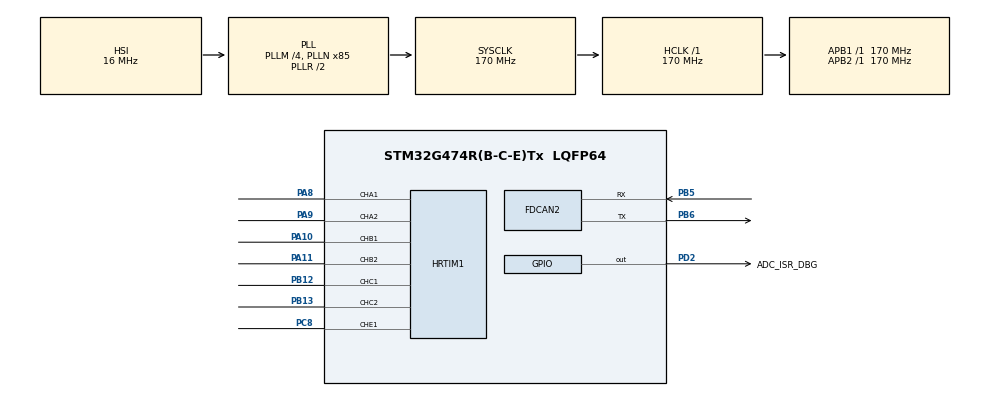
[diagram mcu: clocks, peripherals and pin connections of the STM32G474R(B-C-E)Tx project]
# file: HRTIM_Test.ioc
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FDCAN2.CalculateBaudRateNominal=499999
FDCAN2.CalculateTimeBitNominal=2000
FDCAN2.CalculateTimeQuantumNominal=58.82352941176471
FDCAN2.NominalPrescaler=10
FDCAN2.NominalTimeSeg1=25
FDCAN2.NominalTimeSeg2=8
HRTIM1.ADCTrigger1_Source1=HRTIM_ADCTRIGGEREVENT13_MASTER_PERIOD
HRTIM1.ADCTrigger_Id1=HRTIM_ADCTRIGGER_1
HRTIM1.CaptureUnit1-No_output_TD=__NULL
HRTIM1.CaptureUnit2-No_output_TD=__NULL
HRTIM1.CompareUnit1-MasterTimer=HRTIM_COMPAREUNIT_1
HRTIM1.CompareUnit1-No_output_TD=HRTIM_COMPAREUNIT_1
HRTIM1.CompareUnit1-Output_TA1TA2=__NULL
HRTIM1.CompareUnit1-Output_TB1TB2=__NULL
HRTIM1.CompareUnit1-Output_TC1TC2=__NULL
HRTIM1.CompareUnit1-Output_TE1=HRTIM_COMPAREUNIT_1
HRTIM1.CompareUnit2-MasterTimer=__NULL
HRTIM1.CompareUnit2-No_output_TD=__NULL
HRTIM1.CompareUnit2-Output_TA1TA2=HRTIM_COMPAREUNIT_2
HRTIM1.CompareUnit2-Output_TC1TC2=HRTIM_COMPAREUNIT_2
HRTIM1.CompareUnit3-MasterTimer=HRTIM_COMPAREUNIT_3
HRTIM1.CompareUnit3-No_output_TD=HRTIM_COMPAREUNIT_3
HRTIM1.CompareUnit3-Output_TA1TA2=__NULL
HRTIM1.CompareUnit3-Output_TC1TC2=__NULL
HRTIM1.CompareUnit4-MasterTimer=__NULL
HRTIM1.CompareUnit4-No_output_TD=__NULL
HRTIM1.CompareValue1-MasterTimer=1100
HRTIM1.CompareValue1-No_output_TD=110
HRTIM1.CompareValue1-Output_TE1=8160
HRTIM1.CompareValue2-Output_TA1TA2=110
HRTIM1.CompareValue2-Output_TC1TC2=359
HRTIM1.CompareValue3-MasterTimer=3000
HRTIM1.CompareValue3-No_output_TD=1100
HRTIM1.DACSynchro-MasterTimer=HRTIM_DACSYNC_NONE
HRTIM1.DACSynchro-Output_TA1TA2=HRTIM_DACSYNC_NONE
HRTIM1.DACSynchro-Output_TC1TC2=HRTIM_DACSYNC_NONE
HRTIM1.DeadTimeInsertion-Output_TA1TA2=HRTIM_TIMDEADTIMEINSERTION_DISABLED
HRTIM1.DeadTimeInsertion-Output_TB1TB2=HRTIM_TIMDEADTIMEINSERTION_DISABLED
HRTIM1.DualChannelDacEnableFake_TA-Output_TA1TA2=HRTIM_TIMER_DCDE_DISABLED
HRTIM1.DualChannelDacEnableFake_TC-Output_TC1TC2=HRTIM_TIMER_DCDE_ENABLED_FAKE1
HRTIM1.Event5-No_output_TD=HRTIM_EVENT_5
HRTIM1.Event5-Output_TA1TA2=HRTIM_EVENT_5
HRTIM1.Event_EEV1=__NULL
HRTIM1.Event_EEV2=__NULL
HRTIM1.Event_EEV3=__NULL
HRTIM1.Event_EEV4=__NULL
HRTIM1.Event_EEV5=HRTIM_EVENT_5
HRTIM1.FastMode_EEV5=HRTIM_EVENTFASTMODE_ENABLE
HRTIM1.FaultLevel1-Output_TA1TA2=HRTIM_OUTPUTFAULTLEVEL_INACTIVE
HRTIM1.Filter5-No_output_TD=HRTIM_TIMEEVFLT_BLANKINGCMP3
HRTIM1.Filter5-Output_TA1TA2=HRTIM_TIMEEVFLT_BLANKINGCMP2
HRTIM1.InterleavedMode-Output_TA1TA2=HRTIM_INTERLEAVED_MODE_DISABLED
HRTIM1.InterleavedMode-Output_TB1TB2=HRTIM_INTERLEAVED_MODE_DISABLED
HRTIM1.InterruptRequests1-Output_TA1TA2=HRTIM_TIM_IT_SET1
HRTIM1.InterruptRequests1_Master=HRTIM_MASTER_IT_NONE
HRTIM1.ModeTimeBase-No_output_TD=HRTIM_MODE_SINGLESHOT_RETRIGGERABLE
HRTIM1.ModeTimeBase-Output_TA1TA2=HRTIM_MODE_SINGLESHOT
HRTIM1.ModeTimeBase-Output_TB1TB2=HRTIM_MODE_SINGLESHOT
HRTIM1.ModeTimeBase-Output_TC1TC2=HRTIM_MODE_SINGLESHOT_RETRIGGERABLE
HRTIM1.ModeTimeBase-Output_TE1=HRTIM_MODE_SINGLESHOT
HRTIM1.NumberADCTriggerSource1=1
HRTIM1.NumberDMARequests_TA=0
HRTIM1.NumberInterruptRequests-Output_TA1TA2=1
HRTIM1.NumberInterruptRequests_Master-MasterTimer=1
HRTIM1.NumberResetSource1-Output_TA1TA2=2
HRTIM1.NumberResetSource1-Output_TB1TB2=1
HRTIM1.NumberResetSource1-Output_TC1TC2=1
HRTIM1.NumberResetSource1-Output_TE1=1
HRTIM1.NumberResetSource2_TA=2
HRTIM1.NumberResetSource2_TB=1
HRTIM1.NumberResetSource2_TC=1
HRTIM1.NumberResetTrigger-No_output_TD=2
HRTIM1.NumberResetTrigger-Output_TA1TA2=1
HRTIM1.NumberResetTrigger-Output_TB1TB2=1
HRTIM1.NumberResetTrigger-Output_TC1TC2=1
HRTIM1.NumberResetTrigger-Output_TE1=1
HRTIM1.NumberSetSource1-Output_TA1TA2=1
HRTIM1.NumberSetSource1-Output_TB1TB2=1
HRTIM1.NumberSetSource1-Output_TC1TC2=1
HRTIM1.NumberSetSource1-Output_TE1=1
HRTIM1.NumberSetSource2_TA=1
HRTIM1.NumberSetSource2_TB=1
HRTIM1.NumberSetSource2_TC=1
HRTIM1.NumberUpdateTrigger-No_output_TD=0
HRTIM1.ORingUpdateSource_ADCTrigger1=HRTIM_ADCTRIGGERUPDATE_MASTER
HRTIM1.Periode_MASTER=5440
HRTIM1.Periode_TA=5440
HRTIM1.Periode_TB=5440
HRTIM1.Periode_TC=5440
HRTIM1.Periode_TD=5440
HRTIM1.Periode_TE=21760
HRTIM1.Polarity1-Output_TA1TA2=HRTIM_OUTPUTPOLARITY_HIGH
HRTIM1.Polarity1-Output_TB1TB2=HRTIM_OUTPUTPOLARITY_LOW
HRTIM1.Polarity2-Output_TA1TA2=HRTIM_OUTPUTPOLARITY_HIGH
HRTIM1.Polarity2-Output_TB1TB2=HRTIM_OUTPUTPOLARITY_LOW
HRTIM1.Polarity_EEV5=HRTIM_EVENTPOLARITY_HIGH
HRTIM1.PreloadEnable-No_output_TD=HRTIM_PRELOAD_DISABLED
HRTIM1.PushPull-Output_TA1TA2=HRTIM_TIMPUSHPULLMODE_ENABLED
HRTIM1.PushPull-Output_TB1TB2=HRTIM_TIMPUSHPULLMODE_ENABLED
HRTIM1.PushPull-Output_TC1TC2=HRTIM_TIMPUSHPULLMODE_ENABLED
HRTIM1.ReSyncUpdate-No_output_TD=HRTIM_TIMERESYNC_UPDATE_UNCONDITIONAL
HRTIM1.ResetOutput1_Source1-Output_TA1TA2=HRTIM_OUTPUTRESET_MASTERCMP3
HRTIM1.ResetOutput1_Source1-Output_TB1TB2=HRTIM_OUTPUTRESET_TIMBEV5_TIMDCMP3
HRTIM1.ResetOutput1_Source1-Output_TC1TC2=HRTIM_OUTPUTRESET_MASTERCMP3
HRTIM1.ResetOutput1_Source1-Output_TE1=HRTIM_OUTPUTRESET_TIMCMP1
HRTIM1.ResetOutput1_Source2-Output_TA1TA2=HRTIM_OUTPUTSET_EEV_5
HRTIM1.ResetOutput2_Source1-Output_TA1TA2=HRTIM_OUTPUTRESET_MASTERCMP3
HRTIM1.ResetOutput2_Source1-Output_TB1TB2=HRTIM_OUTPUTRESET_TIMBEV5_TIMDCMP3
HRTIM1.ResetOutput2_Source1-Output_TC1TC2=HRTIM_OUTPUTRESET_MASTERCMP3
HRTIM1.ResetOutput2_Source2-Output_TA1TA2=HRTIM_OUTPUTSET_EEV_5
HRTIM1.ResetTrigger1-No_output_TD=HRTIM_TIMRESETTRIGGER_MASTER_CMP3
HRTIM1.ResetTrigger1-Output_TA1TA2=HRTIM_TIMRESETTRIGGER_MASTER_PER
HRTIM1.ResetTrigger1-Output_TB1TB2=HRTIM_TIMRESETTRIGGER_MASTER_PER
HRTIM1.ResetTrigger1-Output_TC1TC2=HRTIM_TIMRESETTRIGGER_MASTER_PER
HRTIM1.ResetTrigger1-Output_TE1=HRTIM_TIMRESETTRIGGER_MASTER_PER
HRTIM1.ResetTrigger2-No_output_TD=HRTIM_TIMRESETTRIGGER_EEV_5
HRTIM1.ResetUpdate-No_output_TD=HRTIM_TIMUPDATEONRESET_DISABLED
HRTIM1.Sensitivity_EEV5=HRTIM_EVENTSENSITIVITY_LEVEL
HRTIM1.SetOutput1_Source1-Output_TA1TA2=HRTIM_OUTPUTSET_MASTERCMP1
HRTIM1.SetOutput1_Source1-Output_TB1TB2=HRTIM_OUTPUTSET_MASTERPER
HRTIM1.SetOutput1_Source1-Output_TC1TC2=HRTIM_OUTPUTSET_MASTERPER
HRTIM1.SetOutput1_Source1-Output_TE1=HRTIM_OUTPUTSET_TIMPER
HRTIM1.SetOutput2_Source1-Output_TA1TA2=HRTIM_OUTPUTSET_MASTERCMP1
HRTIM1.SetOutput2_Source1-Output_TB1TB2=HRTIM_OUTPUTSET_MASTERPER
HRTIM1.SetOutput2_Source1-Output_TC1TC2=HRTIM_OUTPUTSET_MASTERPER
HRTIM1.UpDownMode-No_output_TD=HRTIM_TIMERUPDOWNMODE_UP
HRTIM1.postscaler1=1
Mcu.Family=STM32G4
Mcu.Name=STM32G474R(B-C-E)Tx
Mcu.Package=LQFP64
NVIC.PriorityGroup=NVIC_PRIORITYGROUP_4
PA10.Mode=Output_TB1TB2
PA10.Signal=HRTIM1_CHB1
PA11.Mode=Output_TB1TB2
PA11.Signal=HRTIM1_CHB2
PA13.GPIO_Label=T_SWDIO
PA13.Signal=SYS_JTMS-SWDIO
PA14.GPIO_Label=T_SWCLK
PA14.Signal=SYS_JTCK-SWCLK
PA8.Mode=Output_TA1TA2
PA8.Signal=HRTIM1_CHA1
PA9.Mode=Output_TA1TA2
PA9.Signal=HRTIM1_CHA2
PB12.Mode=Output_TC1TC2
PB12.Signal=HRTIM1_CHC1
PB13.Mode=Output_TC1TC2
PB13.Signal=HRTIM1_CHC2
PB3.GPIO_Label=T_SWO
PB3.Signal=SYS_JTDO-SWO
PB5.Mode=FDCAN_Activate
PB5.Signal=FDCAN2_RX
PB6.Mode=FDCAN_Activate
PB6.Signal=FDCAN2_TX
PC8.Mode=Output_TE1
PC8.Signal=HRTIM1_CHE1
PD2.GPIO_Label=ADC_ISR_DBG
PD2.GPIO_Speed=GPIO_SPEED_FREQ_VERY_HIGH
PD2.PinState=GPIO_PIN_RESET
PD2.Signal=GPIO_Output
ProjectManager.HeapSize=0x200
ProjectManager.StackSize=0x400
ProjectManager.TargetToolchain=STM32CubeIDE
RCC.ADC12Freq_Value=170000000
RCC.ADC345Freq_Value=170000000
RCC.AHBFreq_Value=170000000
RCC.APB1Freq_Value=170000000
RCC.APB1TimFreq_Value=170000000
RCC.APB2Freq_Value=170000000
RCC.APB2TimFreq_Value=170000000
RCC.CortexFreq_Value=170000000
RCC.EXTERNAL_CLOCK_VALUE=12288000
RCC.HCLKFreq_Value=170000000
RCC.HSE_VALUE=24000000
RCC.HSI48_VALUE=48000000
RCC.HSI_VALUE=16000000
RCC.LSE_VALUE=32768
RCC.PLLM=RCC_PLLM_DIV4
RCC.PLLN=85
RCC.RTCClockSelection=RCC_RTCCLKSOURCE_LSE
RCC.SYSCLKFreq_VALUE=170000000
RCC.SYSCLKSource=RCC_SYSCLKSOURCE_PLLCLK
RCC.USBFreq_Value=170000000
RCC.VCOOutputFreq_Value=340000000
VP_HRTIM1_VS_hrtimMasterTimerNoOutput.Mode=MasterTimer
VP_HRTIM1_VS_hrtimTimerDNoOutput.Mode=No_output_TD
VP_SYS_VS_DBSignals.Mode=DisableDeadBatterySignals
board=NUCLEO-G474RE

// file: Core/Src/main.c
/* USER CODE BEGIN Header */
/**
 ******************************************************************************
 * @file           : main.c
 * @brief          : Main program body
 ******************************************************************************
 * @attention
 *
 * Copyright (c) 2025 STMicroelectronics.
 * All rights reserved.
 *
 * This software is licensed under terms that can be found in the LICENSE file
 * in the root directory of this software component.
 * If no LICENSE file comes with this software, it is provided AS-IS.
 *
 ******************************************************************************
 */
/* USER CODE END Header */
#include "main.h"

FDCAN_HandleTypeDef hfdcan2;

HRTIM_HandleTypeDef hhrtim1;

void SystemClock_Config(void);
static void MX_GPIO_Init(void);
static void MX_HRTIM1_Init(void);
static void MX_FDCAN2_Init(void);

int main(void)
{

  /* MCU Configuration--------------------------------------------------------*/

  /* Reset of all peripherals, Initializes the Flash interface and the Systick. */
  HAL_Init();

  /* Configure the system clock */
  SystemClock_Config();

  /* Initialize all configured peripherals */
  MX_GPIO_Init();
  MX_HRTIM1_Init();
  MX_FDCAN2_Init();
  /* USER CODE BEGIN 2 */

    app_init();

  /* USER CODE END 2 */

  /* Infinite loop */
  /* USER CODE BEGIN WHILE */
    while (1) {
        app_loop();
    /* USER CODE END WHILE */

    }
}

void SystemClock_Config(void)
{
  RCC_OscInitTypeDef RCC_OscInitStruct = {0};
  RCC_ClkInitTypeDef RCC_ClkInitStruct = {0};

  /** Configure the main internal regulator output voltage
  */
  HAL_PWREx_ControlVoltageScaling(PWR_REGULATOR_VOLTAGE_SCALE1_BOOST);

  /** Initializes the RCC Oscillators according to the specified parameters
  * in the RCC_OscInitTypeDef structure.
  */
  RCC_OscInitStruct.OscillatorType = RCC_OSCILLATORTYPE_HSI;
  RCC_OscInitStruct.HSIState = RCC_HSI_ON;
  RCC_OscInitStruct.HSICalibrationValue = RCC_HSICALIBRATION_DEFAULT;
  RCC_OscInitStruct.PLL.PLLState = RCC_PLL_ON;
  RCC_OscInitStruct.PLL.PLLSource = RCC_PLLSOURCE_HSI;
  RCC_OscInitStruct.PLL.PLLM = RCC_PLLM_DIV4;
  RCC_OscInitStruct.PLL.PLLN = 85;
  RCC_OscInitStruct.PLL.PLLP = RCC_PLLP_DIV2;
  RCC_OscInitStruct.PLL.PLLQ = RCC_PLLQ_DIV2;
  RCC_OscInitStruct.PLL.PLLR = RCC_PLLR_DIV2;
  if (HAL_RCC_OscConfig(&RCC_OscInitStruct) != HAL_OK)
  {
    Error_Handler();
  }

  /** Initializes the CPU, AHB and APB buses clocks
  */
  RCC_ClkInitStruct.ClockType = RCC_CLOCKTYPE_HCLK|RCC_CLOCKTYPE_SYSCLK
                              |RCC_CLOCKTYPE_PCLK1|RCC_CLOCKTYPE_PCLK2;
  RCC_ClkInitStruct.SYSCLKSource = RCC_SYSCLKSOURCE_PLLCLK;
  RCC_ClkInitStruct.AHBCLKDivider = RCC_SYSCLK_DIV1;
  RCC_ClkInitStruct.APB1CLKDivider = RCC_HCLK_DIV1;
  RCC_ClkInitStruct.APB2CLKDivider = RCC_HCLK_DIV1;

  if (HAL_RCC_ClockConfig(&RCC_ClkInitStruct, FLASH_LATENCY_4) != HAL_OK)
  {
    Error_Handler();
  }
}

static void MX_FDCAN2_Init(void)
{

  hfdcan2.Instance = FDCAN2;
  hfdcan2.Init.ClockDivider = FDCAN_CLOCK_DIV1;
  hfdcan2.Init.FrameFormat = FDCAN_FRAME_CLASSIC;
  hfdcan2.Init.Mode = FDCAN_MODE_NORMAL;
  hfdcan2.Init.AutoRetransmission = DISABLE;
  hfdcan2.Init.TransmitPause = DISABLE;
  hfdcan2.Init.ProtocolException = DISABLE;
  hfdcan2.Init.NominalPrescaler = 10;
  hfdcan2.Init.NominalSyncJumpWidth = 1;
  hfdcan2.Init.NominalTimeSeg1 = 25;
  hfdcan2.Init.NominalTimeSeg2 = 8;
  hfdcan2.Init.DataPrescaler = 1;
  hfdcan2.Init.DataSyncJumpWidth = 1;
  hfdcan2.Init.DataTimeSeg1 = 1;
  hfdcan2.Init.DataTimeSeg2 = 1;
  hfdcan2.Init.StdFiltersNbr = 0;
  hfdcan2.Init.ExtFiltersNbr = 0;
  hfdcan2.Init.TxFifoQueueMode = FDCAN_TX_FIFO_OPERATION;
  if (HAL_FDCAN_Init(&hfdcan2) != HAL_OK)
  {
    Error_Handler();
  }

}

static void MX_HRTIM1_Init(void)
{

  HRTIM_EventCfgTypeDef pEventCfg = {0};
  HRTIM_ADCTriggerCfgTypeDef pADCTriggerCfg = {0};
  HRTIM_TimeBaseCfgTypeDef pTimeBaseCfg = {0};
  HRTIM_TimerCfgTypeDef pTimerCfg = {0};
  HRTIM_CompareCfgTypeDef pCompareCfg = {0};
  HRTIM_TimerCtlTypeDef pTimerCtl = {0};
  HRTIM_TimerEventFilteringCfgTypeDef pTimerEventFilteringCfg = {0};
  HRTIM_OutputCfgTypeDef pOutputCfg = {0};

  hhrtim1.Instance = HRTIM1;
  hhrtim1.Init.HRTIMInterruptResquests = HRTIM_IT_NONE;
  hhrtim1.Init.SyncOptions = HRTIM_SYNCOPTION_NONE;
  if (HAL_HRTIM_Init(&hhrtim1) != HAL_OK)
  {
    Error_Handler();
  }
  if (HAL_HRTIM_DLLCalibrationStart(&hhrtim1, HRTIM_CALIBRATIONRATE_3) != HAL_OK)
  {
    Error_Handler();
  }
  if (HAL_HRTIM_PollForDLLCalibration(&hhrtim1, 10) != HAL_OK)
  {
    Error_Handler();
  }
  if (HAL_HRTIM_EventPrescalerConfig(&hhrtim1, HRTIM_EVENTPRESCALER_DIV1) != HAL_OK)
  {
    Error_Handler();
  }
  pEventCfg.Source = HRTIM_EEV5SRC_COMP3_OUT;
  pEventCfg.Polarity = HRTIM_EVENTPOLARITY_HIGH;
  pEventCfg.Sensitivity = HRTIM_EVENTSENSITIVITY_LEVEL;
  pEventCfg.FastMode = HRTIM_EVENTFASTMODE_ENABLE;
  if (HAL_HRTIM_EventConfig(&hhrtim1, HRTIM_EVENT_5, &pEventCfg) != HAL_OK)
  {
    Error_Handler();
  }
  pADCTriggerCfg.UpdateSource = HRTIM_ADCTRIGGERUPDATE_MASTER;
  pADCTriggerCfg.Trigger = HRTIM_ADCTRIGGEREVENT13_MASTER_PERIOD;
  if (HAL_HRTIM_ADCTriggerConfig(&hhrtim1, HRTIM_ADCTRIGGER_1, &pADCTriggerCfg) != HAL_OK)
  {
    Error_Handler();
  }
  if (HAL_HRTIM_ADCPostScalerConfig(&hhrtim1, HRTIM_ADCTRIGGER_1, 1) != HAL_OK)
  {
    Error_Handler();
  }
  pTimeBaseCfg.Period = 5440;
  pTimeBaseCfg.RepetitionCounter = 0x00;
  pTimeBaseCfg.PrescalerRatio = HRTIM_PRESCALERRATIO_MUL32;
  pTimeBaseCfg.Mode = HRTIM_MODE_CONTINUOUS;
  if (HAL_HRTIM_TimeBaseConfig(&hhrtim1, HRTIM_TIMERINDEX_MASTER, &pTimeBaseCfg) != HAL_OK)
  {
    Error_Handler();
  }
  pTimerCfg.InterruptRequests = HRTIM_MASTER_IT_NONE;
  pTimerCfg.DMARequests = HRTIM_MASTER_DMA_NONE;
  pTimerCfg.DMASrcAddress = 0x0000;
  pTimerCfg.DMADstAddress = 0x0000;
  pTimerCfg.DMASize = 0x1;
  pTimerCfg.HalfModeEnable = HRTIM_HALFMODE_DISABLED;
  pTimerCfg.InterleavedMode = HRTIM_INTERLEAVED_MODE_DISABLED;
  pTimerCfg.StartOnSync = HRTIM_SYNCSTART_DISABLED;
  pTimerCfg.ResetOnSync = HRTIM_SYNCRESET_DISABLED;
  pTimerCfg.DACSynchro = HRTIM_DACSYNC_NONE;
  pTimerCfg.PreloadEnable = HRTIM_PRELOAD_DISABLED;
  pTimerCfg.UpdateGating = HRTIM_UPDATEGATING_INDEPENDENT;
  pTimerCfg.BurstMode = HRTIM_TIMERBURSTMODE_MAINTAINCLOCK;
  pTimerCfg.RepetitionUpdate = HRTIM_UPDATEONREPETITION_DISABLED;
  pTimerCfg.ReSyncUpdate = HRTIM_TIMERESYNC_UPDATE_UNCONDITIONAL;
  if (HAL_HRTIM_WaveformTimerConfig(&hhrtim1, HRTIM_TIMERINDEX_MASTER, &pTimerCfg) != HAL_OK)
  {
    Error_Handler();
  }
  pCompareCfg.CompareValue = 1100;
  if (HAL_HRTIM_WaveformCompareConfig(&hhrtim1, HRTIM_TIMERINDEX_MASTER, HRTIM_COMPAREUNIT_1, &pCompareCfg) != HAL_OK)
  {
    Error_Handler();
  }
  pCompareCfg.CompareValue = 3000;
  if (HAL_HRTIM_WaveformCompareConfig(&hhrtim1, HRTIM_TIMERINDEX_MASTER, HRTIM_COMPAREUNIT_3, &pCompareCfg) != HAL_OK)
  {
    Error_Handler();
  }
  pTimeBaseCfg.Mode = HRTIM_MODE_SINGLESHOT;
  if (HAL_HRTIM_TimeBaseConfig(&hhrtim1, HRTIM_TIMERINDEX_TIMER_A, &pTimeBaseCfg) != HAL_OK)
  {
    Error_Handler();
  }
  pTimerCtl.UpDownMode = HRTIM_TIMERUPDOWNMODE_UP;
  pTimerCtl.TrigHalf = HRTIM_TIMERTRIGHALF_DISABLED;
  pTimerCtl.DualChannelDacEnable = HRTIM_TIMER_DCDE_DISABLED;
  if (HAL_HRTIM_WaveformTimerControl(&hhrtim1, HRTIM_TIMERINDEX_TIMER_A, &pTimerCtl) != HAL_OK)
  {
    Error_Handler();
  }
  pTimerCfg.InterruptRequests = HRTIM_TIM_IT_SET1;
  pTimerCfg.DMARequests = HRTIM_TIM_DMA_NONE;
  pTimerCfg.PushPull = HRTIM_TIMPUSHPULLMODE_ENABLED;
  pTimerCfg.FaultEnable = HRTIM_TIMFAULTENABLE_NONE;
  pTimerCfg.FaultLock = HRTIM_TIMFAULTLOCK_READWRITE;
  pTimerCfg.DeadTimeInsertion = HRTIM_TIMDEADTIMEINSERTION_DISABLED;
  pTimerCfg.DelayedProtectionMode = HRTIM_TIMER_A_B_C_DELAYEDPROTECTION_DISABLED;
  pTimerCfg.UpdateTrigger = HRTIM_TIMUPDATETRIGGER_NONE;
  pTimerCfg.ResetTrigger = HRTIM_TIMRESETTRIGGER_MASTER_PER;
  pTimerCfg.ResetUpdate = HRTIM_TIMUPDATEONRESET_DISABLED;
  if (HAL_HRTIM_WaveformTimerConfig(&hhrtim1, HRTIM_TIMERINDEX_TIMER_A, &pTimerCfg) != HAL_OK)
  {
    Error_Handler();
  }
  pTimerCfg.InterruptRequests = HRTIM_TIM_IT_NONE;
  if (HAL_HRTIM_WaveformTimerConfig(&hhrtim1, HRTIM_TIMERINDEX_TIMER_B, &pTimerCfg) != HAL_OK)
  {
    Error_Handler();
  }
  if (HAL_HRTIM_WaveformTimerConfig(&hhrtim1, HRTIM_TIMERINDEX_TIMER_C, &pTimerCfg) != HAL_OK)
  {
    Error_Handler();
  }
  pTimerCfg.PushPull = HRTIM_TIMPUSHPULLMODE_DISABLED;
  pTimerCfg.DelayedProtectionMode = HRTIM_TIMER_D_E_DELAYEDPROTECTION_DISABLED;
  pTimerCfg.ResetTrigger = HRTIM_TIMRESETTRIGGER_MASTER_CMP3|HRTIM_TIMRESETTRIGGER_EEV_5;
  if (HAL_HRTIM_WaveformTimerConfig(&hhrtim1, HRTIM_TIMERINDEX_TIMER_D, &pTimerCfg) != HAL_OK)
  {
    Error_Handler();
  }
  pTimerCfg.ResetTrigger = HRTIM_TIMRESETTRIGGER_MASTER_PER;
  if (HAL_HRTIM_WaveformTimerConfig(&hhrtim1, HRTIM_TIMERINDEX_TIMER_E, &pTimerCfg) != HAL_OK)
  {
    Error_Handler();
  }
  pCompareCfg.CompareValue = 110;
  pCompareCfg.AutoDelayedMode = HRTIM_AUTODELAYEDMODE_REGULAR;
  pCompareCfg.AutoDelayedTimeout = 0x0000;

  if (HAL_HRTIM_WaveformCompareConfig(&hhrtim1, HRTIM_TIMERINDEX_TIMER_A, HRTIM_COMPAREUNIT_2, &pCompareCfg) != HAL_OK)
  {
    Error_Handler();
  }
  pTimerEventFilteringCfg.Filter = HRTIM_TIMEEVFLT_BLANKINGCMP2;
  pTimerEventFilteringCfg.Latch = HRTIM_TIMEVENTLATCH_DISABLED;
  if (HAL_HRTIM_TimerEventFilteringConfig(&hhrtim1, HRTIM_TIMERINDEX_TIMER_A, HRTIM_EVENT_5, &pTimerEventFilteringCfg) != HAL_OK)
  {
    Error_Handler();
  }
  pTimerEventFilteringCfg.Filter = HRTIM_TIMEEVFLT_BLANKINGCMP3;
  if (HAL_HRTIM_TimerEventFilteringConfig(&hhrtim1, HRTIM_TIMERINDEX_TIMER_D, HRTIM_EVENT_5, &pTimerEventFilteringCfg) != HAL_OK)
  {
    Error_Handler();
  }
  pOutputCfg.Polarity = HRTIM_OUTPUTPOLARITY_HIGH;
  pOutputCfg.SetSource = HRTIM_OUTPUTSET_MASTERCMP1;
  pOutputCfg.ResetSource = HRTIM_OUTPUTRESET_MASTERCMP3|HRTIM_OUTPUTSET_EEV_5;
  pOutputCfg.IdleMode = HRTIM_OUTPUTIDLEMODE_NONE;
  pOutputCfg.IdleLevel = HRTIM_OUTPUTIDLELEVEL_INACTIVE;
  pOutputCfg.FaultLevel = HRTIM_OUTPUTFAULTLEVEL_INACTIVE;
  pOutputCfg.ChopperModeEnable = HRTIM_OUTPUTCHOPPERMODE_DISABLED;
  pOutputCfg.BurstModeEntryDelayed = HRTIM_OUTPUTBURSTMODEENTRY_REGULAR;
  if (HAL_HRTIM_WaveformOutputConfig(&hhrtim1, HRTIM_TIMERINDEX_TIMER_A, HRTIM_OUTPUT_TA1, &pOutputCfg) != HAL_OK)
  {
    Error_Handler();
  }
  pOutputCfg.Polarity = HRTIM_OUTPUTPOLARITY_LOW;
  pOutputCfg.SetSource = HRTIM_OUTPUTSET_MASTERPER;
  pOutputCfg.ResetSource = HRTIM_OUTPUTRESET_TIMBEV5_TIMDCMP3;
  pOutputCfg.FaultLevel = HRTIM_OUTPUTFAULTLEVEL_NONE;
  if (HAL_HRTIM_WaveformOutputConfig(&hhrtim1, HRTIM_TIMERINDEX_TIMER_B, HRTIM_OUTPUT_TB1, &pOutputCfg) != HAL_OK)
  {
    Error_Handler();
  }
  pOutputCfg.Polarity = HRTIM_OUTPUTPOLARITY_HIGH;
  pOutputCfg.ResetSource = HRTIM_OUTPUTRESET_MASTERCMP3;
  if (HAL_HRTIM_WaveformOutputConfig(&hhrtim1, HRTIM_TIMERINDEX_TIMER_C, HRTIM_OUTPUT_TC1, &pOutputCfg) != HAL_OK)
  {
    Error_Handler();
  }
  pOutputCfg.SetSource = HRTIM_OUTPUTSET_TIMPER;
  pOutputCfg.ResetSource = HRTIM_OUTPUTRESET_TIMCMP1;
  if (HAL_HRTIM_WaveformOutputConfig(&hhrtim1, HRTIM_TIMERINDEX_TIMER_E, HRTIM_OUTPUT_TE1, &pOutputCfg) != HAL_OK)
  {
    Error_Handler();
  }
  pOutputCfg.SetSource = HRTIM_OUTPUTSET_MASTERCMP1;
  pOutputCfg.ResetSource = HRTIM_OUTPUTRESET_MASTERCMP3|HRTIM_OUTPUTSET_EEV_5;
  if (HAL_HRTIM_WaveformOutputConfig(&hhrtim1, HRTIM_TIMERINDEX_TIMER_A, HRTIM_OUTPUT_TA2, &pOutputCfg) != HAL_OK)
  {
    Error_Handler();
  }
  pOutputCfg.Polarity = HRTIM_OUTPUTPOLARITY_LOW;
  pOutputCfg.SetSource = HRTIM_OUTPUTSET_MASTERPER;
  pOutputCfg.ResetSource = HRTIM_OUTPUTRESET_TIMBEV5_TIMDCMP3;
  if (HAL_HRTIM_WaveformOutputConfig(&hhrtim1, HRTIM_TIMERINDEX_TIMER_B, HRTIM_OUTPUT_TB2, &pOutputCfg) != HAL_OK)
  {
    Error_Handler();
  }
  pOutputCfg.Polarity = HRTIM_OUTPUTPOLARITY_HIGH;
  pOutputCfg.ResetSource = HRTIM_OUTPUTRESET_MASTERCMP3;
  if (HAL_HRTIM_WaveformOutputConfig(&hhrtim1, HRTIM_TIMERINDEX_TIMER_C, HRTIM_OUTPUT_TC2, &pOutputCfg) != HAL_OK)
  {
    Error_Handler();
  }
  if (HAL_HRTIM_TimeBaseConfig(&hhrtim1, HRTIM_TIMERINDEX_TIMER_B, &pTimeBaseCfg) != HAL_OK)
  {
    Error_Handler();
  }
  if (HAL_HRTIM_WaveformTimerControl(&hhrtim1, HRTIM_TIMERINDEX_TIMER_B, &pTimerCtl) != HAL_OK)
  {
    Error_Handler();
  }
  pTimeBaseCfg.Mode = HRTIM_MODE_SINGLESHOT_RETRIGGERABLE;
  if (HAL_HRTIM_TimeBaseConfig(&hhrtim1, HRTIM_TIMERINDEX_TIMER_C, &pTimeBaseCfg) != HAL_OK)
  {
    Error_Handler();
  }
  pTimerCtl.DualChannelDacReset = HRTIM_TIMER_DCDR_COUNTER;
  pTimerCtl.DualChannelDacStep = HRTIM_TIMER_DCDS_CMP2;
  pTimerCtl.DualChannelDacEnable = HRTIM_TIMER_DCDE_ENABLED;
  if (HAL_HRTIM_WaveformTimerControl(&hhrtim1, HRTIM_TIMERINDEX_TIMER_C, &pTimerCtl) != HAL_OK)
  {
    Error_Handler();
  }
  pCompareCfg.CompareValue = 359;

  if (HAL_HRTIM_WaveformCompareConfig(&hhrtim1, HRTIM_TIMERINDEX_TIMER_C, HRTIM_COMPAREUNIT_2, &pCompareCfg) != HAL_OK)
  {
    Error_Handler();
  }
  if (HAL_HRTIM_TimeBaseConfig(&hhrtim1, HRTIM_TIMERINDEX_TIMER_D, &pTimeBaseCfg) != HAL_OK)
  {
    Error_Handler();
  }
  pTimerCtl.DualChannelDacEnable = HRTIM_TIMER_DCDE_DISABLED;
  if (HAL_HRTIM_WaveformTimerControl(&hhrtim1, HRTIM_TIMERINDEX_TIMER_D, &pTimerCtl) != HAL_OK)
  {
    Error_Handler();
  }
  pCompareCfg.CompareValue = 110;
  if (HAL_HRTIM_WaveformCompareConfig(&hhrtim1, HRTIM_TIMERINDEX_TIMER_D, HRTIM_COMPAREUNIT_1, &pCompareCfg) != HAL_OK)
  {
    Error_Handler();
  }
  pCompareCfg.CompareValue = 1100;
  if (HAL_HRTIM_WaveformCompareConfig(&hhrtim1, HRTIM_TIMERINDEX_TIMER_D, HRTIM_COMPAREUNIT_3, &pCompareCfg) != HAL_OK)
  {
    Error_Handler();
  }
  pTimeBaseCfg.Period = 21760;
  pTimeBaseCfg.Mode = HRTIM_MODE_SINGLESHOT;
  if (HAL_HRTIM_TimeBaseConfig(&hhrtim1, HRTIM_TIMERINDEX_TIMER_E, &pTimeBaseCfg) != HAL_OK)
  {
    Error_Handler();
  }
  pTimerCtl.GreaterCMP1 = HRTIM_TIMERGTCMP1_EQUAL;
  if (HAL_HRTIM_WaveformTimerControl(&hhrtim1, HRTIM_TIMERINDEX_TIMER_E, &pTimerCtl) != HAL_OK)
  {
    Error_Handler();
  }
  pCompareCfg.CompareValue = 8160;
  if (HAL_HRTIM_WaveformCompareConfig(&hhrtim1, HRTIM_TIMERINDEX_TIMER_E, HRTIM_COMPAREUNIT_1, &pCompareCfg) != HAL_OK)
  {
    Error_Handler();
  }
  HAL_HRTIM_MspPostInit(&hhrtim1);

}

static void MX_GPIO_Init(void)
{
  GPIO_InitTypeDef GPIO_InitStruct = {0};

  /* GPIO Ports Clock Enable */
  __HAL_RCC_GPIOB_CLK_ENABLE();
  __HAL_RCC_GPIOC_CLK_ENABLE();
  __HAL_RCC_GPIOA_CLK_ENABLE();
  __HAL_RCC_GPIOD_CLK_ENABLE();

  /*Configure GPIO pin Output Level */
  HAL_GPIO_WritePin(ADC_ISR_DBG_GPIO_Port, ADC_ISR_DBG_Pin, GPIO_PIN_RESET);

  /*Configure GPIO pin : ADC_ISR_DBG_Pin */
  GPIO_InitStruct.Pin = ADC_ISR_DBG_Pin;
  GPIO_InitStruct.Mode = GPIO_MODE_OUTPUT_PP;
  GPIO_InitStruct.Pull = GPIO_NOPULL;
  GPIO_InitStruct.Speed = GPIO_SPEED_FREQ_VERY_HIGH;
  HAL_GPIO_Init(ADC_ISR_DBG_GPIO_Port, &GPIO_InitStruct);

}

void Error_Handler(void)
{
    __disable_irq();
    while (1) {
    }
}
